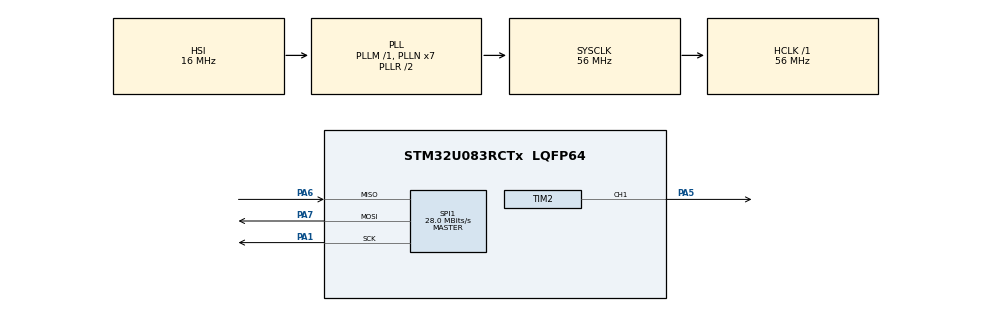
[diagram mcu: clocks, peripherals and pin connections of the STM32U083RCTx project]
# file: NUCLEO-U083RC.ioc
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ADC1.Channel-0\#ChannelRegularConversion=ADC_CHANNEL_TEMPSENSOR
ADC1.NbrOfConversionFlag=1
ADC1.Rank-0\#ChannelRegularConversion=1
ADC1.RankArg-0\#ChannelRegularConversion=ADC_REGULAR_RANK_1
ADC1.SamplingTime-0\#ChannelRegularConversion=ADC_SAMPLINGTIME_COMMON_1
ADC1.SelectedChannel=ADC_CHANNEL_TEMPSENSOR
ADC1.master=1
Mcu.Family=STM32U0
Mcu.Name=STM32U083RCTx
Mcu.Package=LQFP64
NUCLEO-U083RC.BUTTON=1
NUCLEO-U083RC.LD4=true
NUCLEO-U083RC.VCP=true
NVIC.EXTI4_15_IRQn=true\:0\:0\:false\:false\:true\:false\:true\:true
NVIC.PriorityGroup=NVIC_PRIORITYGROUP_2
PA1.Mode=Full_Duplex_Master
PA1.Signal=SPI1_SCK
PA13\ (SWDIO).GPIO_Label=SWDIO
PA13\ (SWDIO).Mode=Serial_Wire
PA13\ (SWDIO).Signal=DEBUG_JTMS-SWDIO
PA14\ (SWCLK).GPIO_Label=SWCLK
PA14\ (SWCLK).Mode=Serial_Wire
PA14\ (SWCLK).Signal=DEBUG_JTCK-SWCLK
PA2.Signal=USART2_TX
PA3.Signal=USART2_RX
PA5.Signal=S_TIM2_CH1_ETR
PA6.Mode=Full_Duplex_Master
PA6.Signal=SPI1_MISO
PA7.Mode=Full_Duplex_Master
PA7.Signal=SPI1_MOSI
PC14-OSC32_IN.GPIO_Label=OSC32_IN
PC14-OSC32_IN.Mode=LSE-External-Oscillator
PC14-OSC32_IN.Signal=RCC_OSC32_IN
PC15-OSC32_OUT.GPIO_Label=OSC32_OUT
PC15-OSC32_OUT.Mode=LSE-External-Oscillator
PC15-OSC32_OUT.Signal=RCC_OSC32_OUT
PF0-OSC_IN.GPIO_Label=OSC_IN
PF0-OSC_IN.Mode=HSE-External-Oscillator
PF0-OSC_IN.Signal=RCC_OSC_IN
PF1-OSC_OUT.GPIO_Label=OSC_OUT
PF1-OSC_OUT.Mode=HSE-External-Oscillator
PF1-OSC_OUT.Signal=RCC_OSC_OUT
ProjectManager.HeapSize=0x200
ProjectManager.StackSize=0x400
ProjectManager.TargetToolchain=CMake
RCC.ADCFreq_Value=56000000
RCC.AHBFreq_Value=56000000
RCC.CortexFreq_Value=56000000
RCC.HCLKFreq_Value=56000000
RCC.HSE_VALUE=4000000
RCC.HSI48_VALUE=48000000
RCC.HSI_VALUE=16000000
RCC.MSI_VALUE=4000000
RCC.PLLN=7
RCC.SYSCLKFreq_VALUE=56000000
RCC.SYSCLKSource=RCC_SYSCLKSOURCE_PLLCLK
RCC.VCOOutputFreq_Value=112000000
SH.S_TIM2_CH1_ETR.0=TIM2_CH1,PWM Generation1 CH1
SPI1.CRCCalculation=SPI_CRCCALCULATION_DISABLE
SPI1.CalculateBaudRate=28.0 MBits/s
SPI1.DataSize=SPI_DATASIZE_8BIT
SPI1.Direction=SPI_DIRECTION_2LINES
SPI1.Mode=SPI_MODE_MASTER
SPI1.VirtualType=VM_MASTER
TIM2.AutoReloadPreload=TIM_AUTORELOAD_PRELOAD_ENABLE
TIM2.Channel-PWM\ Generation1\ CH1=TIM_CHANNEL_1
TIM2.Period=1000-1
TIM2.Prescaler=56-1
VP_ADC1_TempSens_Input.Mode=IN-TempSens
VP_NUCLEO-U083RC_VS_BSP_COMMON.Mode=COMMON
VP_PWR_VS_SECSignals.Mode=Security/Privilege
VP_TIM2_VS_ClockSourceINT.Mode=Internal
board=NUCLEO-U083RC

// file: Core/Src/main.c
/* USER CODE BEGIN Header */
/**
  ******************************************************************************
  * @file           : main.c
  * @brief          : Main program body
  ******************************************************************************
  * @attention
  *
  * Copyright (c) 2026 STMicroelectronics.
  * All rights reserved.
  *
  * This software is licensed under terms that can be found in the LICENSE file
  * in the root directory of this software component.
  * If no LICENSE file comes with this software, it is provided AS-IS.
  *
  ******************************************************************************
  */
/* USER CODE END Header */
#include "main.h"
#include "adc.h"
#include "spi.h"
#include "tim.h"
#include "gpio.h"

COM_InitTypeDef BspCOMInit;

void SystemClock_Config(void);

/* USER CODE BEGIN 0 */
int _write(int file, char *ptr, int len)
{
  HAL_UART_Transmit(&hcom_uart[COM1], (const uint8_t*)ptr, len, 100);
  return 0;
}
/* USER CODE END 0 */

int main(void)
{

  /* MCU Configuration--------------------------------------------------------*/

  /* Reset of all peripherals, Initializes the Flash interface and the Systick. */
  HAL_Init();

  /* Configure the system clock */
  SystemClock_Config();

  /* Initialize all configured peripherals */
  MX_GPIO_Init();
  MX_ADC1_Init();
  MX_SPI1_Init();
  MX_TIM2_Init();
  /* USER CODE BEGIN 2 */

  // TIM2의 PWM 채널 1을 시작합니다.
  HAL_TIM_PWM_Start(&htim2, TIM_CHANNEL_1);

  /* USER CODE END 2 */

  /* Initialize USER push-button, will be used to trigger an interrupt each time it's pressed.*/
  BSP_PB_Init(BUTTON_USER, BUTTON_MODE_EXTI);

  /* Initialize COM1 port (115200, 8 bits (7-bit data + 1 stop bit), no parity */
  BspCOMInit.BaudRate   = 115200;
  BspCOMInit.WordLength = COM_WORDLENGTH_8B;
  BspCOMInit.StopBits   = COM_STOPBITS_1;
  BspCOMInit.Parity     = COM_PARITY_NONE;
  BspCOMInit.HwFlowCtl  = COM_HWCONTROL_NONE;
  if (BSP_COM_Init(COM1, &BspCOMInit) != BSP_ERROR_NONE)
  {
    Error_Handler();
  }

  /* Infinite loop */
  /* USER CODE BEGIN WHILE */
  while (1)
  {
    // LED 밝기를 서서히 증가시킵니다.
    for (uint32_t i = 0; i < 1000; i++)
    {
      __HAL_TIM_SET_COMPARE(&htim2, TIM_CHANNEL_1, i);
      HAL_Delay(1); // 1ms 지연
    }

    // LED 밝기를 서서히 감소시킵니다.
    for (uint32_t i = 1000; i > 0; i--)
    {
      __HAL_TIM_SET_COMPARE(&htim2, TIM_CHANNEL_1, i);
      HAL_Delay(1); // 1ms 지연
    }
    /* USER CODE END WHILE */

  }
}

void SystemClock_Config(void)
{
  RCC_OscInitTypeDef RCC_OscInitStruct = {0};
  RCC_ClkInitTypeDef RCC_ClkInitStruct = {0};

  /** Configure the main internal regulator output voltage
  */
  HAL_PWREx_ControlVoltageScaling(PWR_REGULATOR_VOLTAGE_SCALE1);

  /** Initializes the RCC Oscillators according to the specified parameters
  * in the RCC_OscInitTypeDef structure.
  */
  RCC_OscInitStruct.OscillatorType = RCC_OSCILLATORTYPE_HSI;
  RCC_OscInitStruct.HSIState = RCC_HSI_ON;
  RCC_OscInitStruct.HSICalibrationValue = RCC_HSICALIBRATION_DEFAULT;
  RCC_OscInitStruct.PLL.PLLState = RCC_PLL_ON;
  RCC_OscInitStruct.PLL.PLLSource = RCC_PLLSOURCE_HSI;
  RCC_OscInitStruct.PLL.PLLM = RCC_PLLM_DIV1;
  RCC_OscInitStruct.PLL.PLLN = 7;
  RCC_OscInitStruct.PLL.PLLP = RCC_PLLP_DIV2;
  RCC_OscInitStruct.PLL.PLLQ = RCC_PLLQ_DIV2;
  RCC_OscInitStruct.PLL.PLLR = RCC_PLLR_DIV2;
  if (HAL_RCC_OscConfig(&RCC_OscInitStruct) != HAL_OK)
  {
    Error_Handler();
  }

  /** Initializes the CPU, AHB and APB buses clocks
  */
  RCC_ClkInitStruct.ClockType = RCC_CLOCKTYPE_HCLK|RCC_CLOCKTYPE_SYSCLK
                              |RCC_CLOCKTYPE_PCLK1;
  RCC_ClkInitStruct.SYSCLKSource = RCC_SYSCLKSOURCE_PLLCLK;
  RCC_ClkInitStruct.AHBCLKDivider = RCC_SYSCLK_DIV1;
  RCC_ClkInitStruct.APB1CLKDivider = RCC_HCLK_DIV1;

  if (HAL_RCC_ClockConfig(&RCC_ClkInitStruct, FLASH_LATENCY_2) != HAL_OK)
  {
    Error_Handler();
  }
}

void Error_Handler(void)
{
  __disable_irq();
  while (1)
  {
  }
}
